# LargeDummyDevice register map
File version: 1.0
Registers are 32-bit, read-write, no defined reset value unless marked. A register's access mark holds for its fields unless they carry their own. Offsets are from the block's base; [hi:lo] are bit positions.

## PERIPHERAL_85
Base 0x40054000
0x04 REG_1 — Register 1
  [29:25] FIELD_4, [27:24] FIELD_2, [20:19] FIELD_1, [9:6] FIELD_3
0x08 REG_2 — Register 2
  [34:31] FIELD_4, [24:23] FIELD_1, [21] FIELD_7, [16:15] FIELD_2, [19:15] FIELD_5, [16:14] FIELD_3, [13:12] FIELD_6, [9] FIELD_8, [3:0] FIELD_9
0x0C REG_3 — Register 3
  [33:30] FIELD_4, [31:29] FIELD_8, [29:28] FIELD_1, [28:26] FIELD_13, [25] FIELD_7, [25:24] FIELD_6, [26:23] FIELD_17, [20:16] FIELD_2, [15] FIELD_14, [17:14] FIELD_11, [17:13] FIELD_10, [16:13] FIELD_12, [15:12] FIELD_16, [14:11] FIELD_3, [10] FIELD_15, [8:4] FIELD_9, [4:1] FIELD_5
0x10 REG_4 — Register 4
  [32:31] FIELD_18, [29] FIELD_20, [31:28] FIELD_13, [27] FIELD_2, [26:25] FIELD_12, [25:23] FIELD_19, [23:22] FIELD_16, [22:20] FIELD_15, [21:19] FIELD_11, [21:18] FIELD_4, [22:18] FIELD_14, [19:17] FIELD_6, [19:17] FIELD_8, [17:16] FIELD_10, [19:16] FIELD_17, [12:10] FIELD_7, [11:9] FIELD_5, [11:7] FIELD_9, [8:7] FIELD_21, [5:2] FIELD_3, [3:1] FIELD_1
0x14 REG_5 — Register 5
  [31] FIELD_16, [35:31] FIELD_24, [32:30] FIELD_7, [32:30] FIELD_8, [31:29] FIELD_21, [30:28] FIELD_17, [29:27] FIELD_12, [23:19] FIELD_3, [22:18] FIELD_13, [19:15] FIELD_2, [17:14] FIELD_18, [16:13] FIELD_9, [16:13] FIELD_23, [13:11] FIELD_19, [12:10] FIELD_15, [8:7] FIELD_14, [7:5] FIELD_5, [5] FIELD_10, [8:4] FIELD_4, [5:4] FIELD_6, [4:3] FIELD_1, [2] FIELD_11, [4:1] FIELD_20, [2:0] FIELD_22
0x18 REG_6 — Register 6
  [23:22] FIELD_3, [18:15] FIELD_1, [16:15] FIELD_2, [9:8] FIELD_4
0x1C REG_7 — Register 7
  [34:31] FIELD_7, [29:28] FIELD_4, [27:24] FIELD_2, [26:23] FIELD_1, [18:17] FIELD_3, [3:2] FIELD_5, [0] FIELD_6
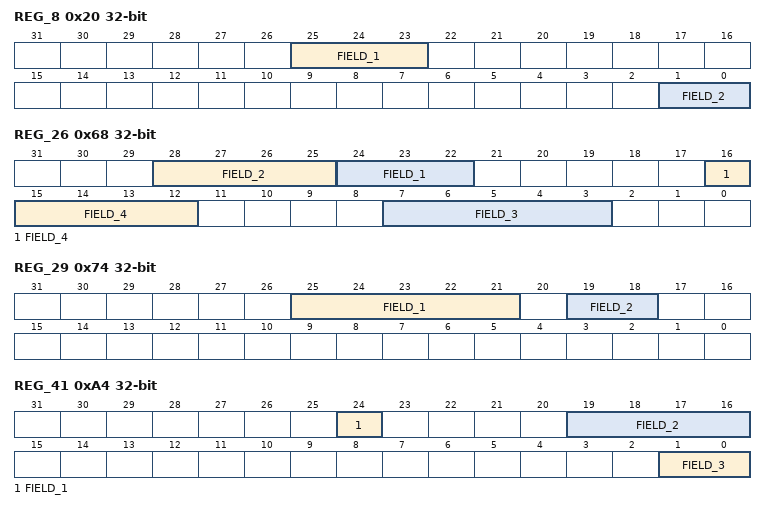
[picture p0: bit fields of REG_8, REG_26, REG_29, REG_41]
0x20 REG_8 — Register 8
  [25:23] FIELD_1, [1:0] FIELD_2
0x24 REG_9 — Register 9
  [18] FIELD_2, [10:8] FIELD_4, [9:7] FIELD_3, [7:4] FIELD_1
0x28 REG_10 — Register 10
  [28] FIELD_1, [32:28] FIELD_2, [16:14] FIELD_6, [8:4] FIELD_3, [0] FIELD_4, [2:0] FIELD_5
0x2C REG_11 — Register 11
  [33:31] FIELD_2, [33:31] FIELD_4, [32:31] FIELD_14, [26:23] FIELD_3, [23:20] FIELD_10, [23:19] FIELD_1, [19:15] FIELD_6, [18:14] FIELD_13, [13] FIELD_9, [13:12] FIELD_12, [10] FIELD_5, [7] FIELD_11, [7] FIELD_15, [6] FIELD_8, [6:4] FIELD_16, [3:0] FIELD_7
0x30 REG_12 — Register 12
  [33:30] FIELD_14, [32:29] FIELD_9, [26:25] FIELD_6, [26:22] FIELD_5, [18:16] FIELD_2, [18:16] FIELD_4, [16] FIELD_10, [19:15] FIELD_1, [15:13] FIELD_3, [15:13] FIELD_13, [12:8] FIELD_8, [9:7] FIELD_12, [5:4] FIELD_7, [4:2] FIELD_11
0x34 REG_13 — Register 13
  [31] FIELD_9, [31:28] FIELD_2, [30:28] FIELD_6, [27:23] FIELD_4, [24:22] FIELD_8, [14] FIELD_5, [15:13] FIELD_10, [10] FIELD_3, [11:9] FIELD_1, [8:5] FIELD_7
0x38 REG_14 — Register 14
  [32:31] FIELD_2, [30:28] FIELD_9, [31:28] FIELD_11, [28:24] FIELD_1, [27:23] FIELD_10, [23:22] FIELD_7, [15:14] FIELD_4, [13:11] FIELD_3, [8:7] FIELD_8, [6:4] FIELD_5, [7:4] FIELD_6, [6:4] FIELD_12, [5:2] FIELD_13, [6:2] FIELD_14
0x3C REG_15 — Register 15
  [33:30] FIELD_11, [33:29] FIELD_4, [30:29] FIELD_9, [28] FIELD_16, [31:27] FIELD_29, [26:24] FIELD_6, [24] FIELD_10, [28:24] FIELD_17, [26:22] FIELD_13, [22:19] FIELD_1, [20:19] FIELD_20, [22:18] FIELD_2, [21:17] FIELD_22, [20:17] FIELD_27, [18:15] FIELD_8, [15] FIELD_26, [14:13] FIELD_5, [14:12] FIELD_19, [13:12] FIELD_21, [11] FIELD_25, [14:10] FIELD_23, [12:8] FIELD_3, [8] FIELD_12, [8:5] FIELD_7, [5:4] FIELD_24, [5:3] FIELD_18, [4:3] FIELD_28, [5:2] FIELD_15, [4:1] FIELD_14
0x40 REG_16 — Register 16
  [33:29] FIELD_1, [33:29] FIELD_16, [31:28] FIELD_14, [29:27] FIELD_7, [25] FIELD_13, [25] FIELD_19, [23:22] FIELD_5, [21:19] FIELD_11, [15:14] FIELD_18, [14:13] FIELD_8, [17:13] FIELD_15, [12] FIELD_21, [11] FIELD_9, [9:7] FIELD_10, [11:7] FIELD_20, [8:6] FIELD_2, [8:4] FIELD_4, [4] FIELD_6, [6:3] FIELD_3, [5:3] FIELD_12, [7:3] FIELD_17
0x44 REG_17 — Register 17
  [28:27] FIELD_8, [26:25] FIELD_3, [23] FIELD_1, [16:15] FIELD_2, [18:14] FIELD_5, [11:10] FIELD_12, [9:7] FIELD_7, [4] FIELD_11, [2] FIELD_4, [6:2] FIELD_6, [2] FIELD_10, [1:0] FIELD_9
0x48 REG_18 — Register 18
  [31:29] FIELD_1, [9] FIELD_4, [4] FIELD_3, [4:2] FIELD_2
0x4C REG_19 — Register 19
  [34:31] FIELD_7, [34:30] FIELD_2, [31:28] FIELD_5, [27] FIELD_10, [27:26] FIELD_4, [26:25] FIELD_8, [28:25] FIELD_12, [27:23] FIELD_16, [27:23] FIELD_24, [23:21] FIELD_1, [23:21] FIELD_22, [20] FIELD_6, [20:18] FIELD_15, [20:17] FIELD_9, [17] FIELD_19, [17] FIELD_21, [15:14] FIELD_18, [16:14] FIELD_20, [14] FIELD_27, [14:13] FIELD_3, [13:11] FIELD_17, [11:9] FIELD_26, [8:7] FIELD_23, [8:5] FIELD_14, [2] FIELD_13, [2] FIELD_25, [3:1] FIELD_11
0x50 REG_20 — Register 20
  [21:19] FIELD_1
0x54 REG_21 — Register 21
  [30:29] FIELD_12, [33:29] FIELD_19, [28:27] FIELD_4, [29:26] FIELD_6, [25] FIELD_7, [24:23] FIELD_5, [25:23] FIELD_8, [22] FIELD_17, [23:21] FIELD_3, [22:18] FIELD_21, [18:17] FIELD_15, [19:17] FIELD_24, [16] FIELD_1, [17:15] FIELD_11, [16:15] FIELD_13, [16:14] FIELD_2, [14] FIELD_9, [16:12] FIELD_14, [12:10] FIELD_20, [13:10] FIELD_22, [10:7] FIELD_25, [7:6] FIELD_10, [6:5] FIELD_18, [3] FIELD_23, [2:1] FIELD_16
0x58 REG_22 — Register 22
  [35:31] FIELD_2, [31] FIELD_15, [30:27] FIELD_1, [27:26] FIELD_7, [27:24] FIELD_8, [24] FIELD_12, [17] FIELD_5, [16] FIELD_9, [17:15] FIELD_3, [11:9] FIELD_14, [10:6] FIELD_13, [7:5] FIELD_10, [6:4] FIELD_11, [3] FIELD_4, [1:0] FIELD_6
0x5C REG_23 — Register 23
  [31:30] FIELD_11, [33:30] FIELD_15, [29] FIELD_19, [29:27] FIELD_4, [29:27] FIELD_5, [28:27] FIELD_7, [31:27] FIELD_10, [31:27] FIELD_20, [26:25] FIELD_16, [29:25] FIELD_21, [28:24] FIELD_14, [23] FIELD_3, [26:23] FIELD_6, [21:19] FIELD_13, [17] FIELD_8, [17:15] FIELD_1, [18:15] FIELD_17, [11:8] FIELD_2, [8:5] FIELD_12, [4] FIELD_18, [3:0] FIELD_9
0x60 REG_24 — Register 24
  [35:31] FIELD_19, [33:29] FIELD_1, [29] FIELD_16, [30:27] FIELD_20, [27:24] FIELD_31, [25:22] FIELD_2, [23:22] FIELD_15, [21] FIELD_3, [22:21] FIELD_13, [19] FIELD_25, [22:18] FIELD_12, [22:18] FIELD_24, [20:17] FIELD_23, [18:17] FIELD_30, [16:15] FIELD_29, [18:14] FIELD_14, [15:12] FIELD_10, [13:12] FIELD_27, [12:10] FIELD_22, [13:9] FIELD_6, [7] FIELD_17, [7] FIELD_21, [9:6] FIELD_8, [7:5] FIELD_18, [4] FIELD_4, [4] FIELD_28, [5:3] FIELD_9, [6:2] FIELD_5, [4:0] FIELD_7, [1:0] FIELD_11, [3:0] FIELD_26
0x64 REG_25 — Register 25
  [26] FIELD_2, [18:15] FIELD_1, [16:12] FIELD_4, [11:7] FIELD_3
0x68 REG_26 — Register 26
  [28:25] FIELD_2, [24:22] FIELD_1, [16:12] FIELD_4, [7:3] FIELD_3
0x6C REG_27 — Register 27
  [35:31] FIELD_7, [30:29] FIELD_3, [28] FIELD_17, [28:26] FIELD_6, [28:26] FIELD_21, [25:24] FIELD_2, [26:22] FIELD_1, [20:19] FIELD_12, [22:18] FIELD_5, [21:18] FIELD_19, [20:16] FIELD_20, [14] FIELD_8, [13:11] FIELD_10, [11:9] FIELD_9, [11:8] FIELD_13, [10:8] FIELD_16, [11:7] FIELD_4, [3:2] FIELD_15, [5:2] FIELD_18, [4:1] FIELD_22, [3:0] FIELD_11, [1:0] FIELD_14
0x70 REG_28 — Register 28
  [31:27] FIELD_1, [28:24] FIELD_2, [26:24] FIELD_4, [15:14] FIELD_3, [14:13] FIELD_6, [14:10] FIELD_5
0x74 REG_29 — Register 29
  [25:21] FIELD_1, [19:18] FIELD_2
0x78 REG_30 — Register 30
  [35:31] FIELD_1, [32:31] FIELD_6, [31:30] FIELD_2, [34:30] FIELD_4, [34:30] FIELD_28, [31:29] FIELD_10, [32:28] FIELD_12, [31:28] FIELD_26, [30:26] FIELD_23, [25] FIELD_20, [22:19] FIELD_3, [20:18] FIELD_22, [17] FIELD_8, [16] FIELD_16, [16:15] FIELD_24, [15] FIELD_29, [19:15] FIELD_30, [13] FIELD_27, [14:12] FIELD_9, [16:12] FIELD_14, [15:12] FIELD_19, [11] FIELD_18, [13:9] FIELD_11, [8] FIELD_15, [11:8] FIELD_17, [10:6] FIELD_21, [7:5] FIELD_13, [5:4] FIELD_5, [7:4] FIELD_7, [5:2] FIELD_25, [4:0] FIELD_31
0x7C REG_31 — Register 31
  [33:31] FIELD_7, [32:29] FIELD_12, [30:28] FIELD_13, [31:27] FIELD_14, [25] FIELD_10, [28:24] FIELD_15, [24:23] FIELD_11, [25:21] FIELD_9, [13] FIELD_2, [17:13] FIELD_4, [12:11] FIELD_16, [14:10] FIELD_3, [9:8] FIELD_1, [9:5] FIELD_5, [6:5] FIELD_6, [3:2] FIELD_8
0x80 REG_32 — Register 32
  [32:29] FIELD_14, [29:28] FIELD_8, [31:27] FIELD_15, [28:27] FIELD_18, [27] FIELD_20, [18:17] FIELD_5, [17] FIELD_11, [20:17] FIELD_13, [20:17] FIELD_19, [14] FIELD_12, [14:13] FIELD_1, [13:11] FIELD_10, [14:10] FIELD_6, [10:7] FIELD_3, [4] FIELD_2, [7:3] FIELD_17, [5:1] FIELD_9, [4:0] FIELD_4, [2:0] FIELD_7, [2:0] FIELD_16
0x84 REG_33 — Register 33
  [32:28] FIELD_9, [28:27] FIELD_8, [30:26] FIELD_3, [28:26] FIELD_5, [23:22] FIELD_13, [22:21] FIELD_11, [13:9] FIELD_1, [10:7] FIELD_4, [6:3] FIELD_2, [5:2] FIELD_6, [3:0] FIELD_7, [4:0] FIELD_10, [3:0] FIELD_12
0x88 REG_34 — Register 34
  [26] FIELD_2, [19:17] FIELD_5, [12:11] FIELD_1, [3:2] FIELD_4, [3:0] FIELD_3
0x8C REG_35 — Register 35
  [31] FIELD_13, [31] FIELD_20, [33:30] FIELD_5, [29:28] FIELD_2, [31:27] FIELD_7, [31:27] FIELD_10, [28:27] FIELD_15, [24] FIELD_26, [26:23] FIELD_25, [24:22] FIELD_28, [20:18] FIELD_8, [18] FIELD_18, [18] FIELD_19, [21:18] FIELD_32, [20:17] FIELD_1, [16] FIELD_3, [15:14] FIELD_11, [18:14] FIELD_30, [13:12] FIELD_12, [12:11] FIELD_16, [8:6] FIELD_4, [6:4] FIELD_22, [4:3] FIELD_17, [3] FIELD_21, [7:3] FIELD_29, [3:2] FIELD_31, [1] FIELD_14, [4:0] FIELD_6, [0] FIELD_9, [2:0] FIELD_23, [4:0] FIELD_24, [4:0] FIELD_27
0x90 REG_36 — Register 36
  [31:28] FIELD_1, [28:27] FIELD_5, [26:25] FIELD_3, [21:18] FIELD_2, [16:14] FIELD_4
0x94 REG_37 — Register 37
  [31:30] FIELD_5, [32:30] FIELD_9, [31:30] FIELD_12, [30:28] FIELD_14, [24:20] FIELD_8, [23:20] FIELD_13, [18:15] FIELD_7, [16:13] FIELD_15, [16:12] FIELD_10, [13:12] FIELD_11, [16:12] FIELD_16, [15:11] FIELD_18, [14:10] FIELD_21, [13:9] FIELD_1, [9] FIELD_17, [11:7] FIELD_6, [10:7] FIELD_20, [5:4] FIELD_3, [7:3] FIELD_2, [3:2] FIELD_19, [4:1] FIELD_4
0x98 REG_38 — Register 38
  [33:31] FIELD_19, [33:31] FIELD_27, [30:29] FIELD_18, [30:27] FIELD_2, [28:24] FIELD_4, [24] FIELD_14, [26:23] FIELD_6, [27:23] FIELD_17, [25:23] FIELD_31, [21] FIELD_3, [21] FIELD_28, [20:19] FIELD_30, [20:18] FIELD_1, [19:18] FIELD_29, [19:17] FIELD_23, [18:15] FIELD_9, [16:15] FIELD_13, [15:14] FIELD_22, [17:13] FIELD_10, [16:13] FIELD_24, [16:13] FIELD_32, [13:11] FIELD_7, [13:10] FIELD_15, [9] FIELD_12, [10:8] FIELD_25, [6] FIELD_11, [9:6] FIELD_26, [8:4] FIELD_20, [4:3] FIELD_5, [6:3] FIELD_8, [3] FIELD_21, [3:1] FIELD_16
0x9C REG_39 — Register 39
  [32:31] FIELD_1, [29] FIELD_11, [29] FIELD_13, [29:25] FIELD_6, [24:23] FIELD_10, [16:14] FIELD_4, [17:14] FIELD_5, [16:12] FIELD_9, [8] FIELD_3, [11:7] FIELD_12, [9:5] FIELD_7, [4] FIELD_8, [7:3] FIELD_2, [4:3] FIELD_14, [2:0] FIELD_15
0xA0 REG_40 — Register 40
  [31:30] FIELD_1, [29] FIELD_10, [30:28] FIELD_14, [28] FIELD_15, [29:25] FIELD_11, [26:24] FIELD_24, [23:22] FIELD_16, [23:21] FIELD_9, [25:21] FIELD_23, [21:17] FIELD_28, [20:16] FIELD_13, [16:15] FIELD_27, [13] FIELD_6, [14:13] FIELD_12, [17:13] FIELD_30, [14:11] FIELD_4, [11] FIELD_7, [13:11] FIELD_22, [14:10] FIELD_21, [12:8] FIELD_18, [10:8] FIELD_20, [8] FIELD_25, [7] FIELD_17, [7] FIELD_29, [10:6] FIELD_5, [7:3] FIELD_26, [5:2] FIELD_8, [5:2] FIELD_19, [4:1] FIELD_2, [4:0] FIELD_3, [4:0] FIELD_31
0xA4 REG_41 — Register 41
  [24] FIELD_1, [19:16] FIELD_2, [1:0] FIELD_3
0xA8 REG_42 — Register 42
  [34:31] FIELD_20, [33:30] FIELD_9, [29] FIELD_3, [31:29] FIELD_14, [31:27] FIELD_6, [28:27] FIELD_17, [24] FIELD_1, [22] FIELD_12, [20:17] FIELD_4, [17:16] FIELD_10, [15:13] FIELD_7, [17:13] FIELD_13, [9] FIELD_16, [10:6] FIELD_15, [9:5] FIELD_11, [7:4] FIELD_19, [7:3] FIELD_8, [4:3] FIELD_18, [4:2] FIELD_2, [2:1] FIELD_5
0xAC REG_43 — Register 43
  [30:29] FIELD_22, [32:28] FIELD_12, [28] FIELD_16, [27] FIELD_8, [29:26] FIELD_20, [29:25] FIELD_13, [26:24] FIELD_21, [23] FIELD_2, [23] FIELD_3, [23:20] FIELD_14, [20] FIELD_19, [22:19] FIELD_5, [21:19] FIELD_9, [20:16] FIELD_4, [18:14] FIELD_18, [12:11] FIELD_11, [8] FIELD_10, [8:4] FIELD_15, [5:3] FIELD_1, [3:2] FIELD_7, [6:2] FIELD_17, [1:0] FIELD_6
0xB0 REG_44 — Register 44
  [29:25] FIELD_17, [26:23] FIELD_3, [21] FIELD_1, [21:19] FIELD_15, [19:18] FIELD_8, [22:18] FIELD_10, [18:17] FIELD_9, [18:17] FIELD_12, [16:15] FIELD_13, [17:13] FIELD_14, [12:11] FIELD_6, [9:7] FIELD_2, [8:7] FIELD_11, [8:5] FIELD_4, [6:5] FIELD_5, [5:2] FIELD_7, [4:0] FIELD_16
0xB4 REG_45 — Register 45
  [31] FIELD_5, [32:29] FIELD_22, [30:28] FIELD_13, [29:27] FIELD_2, [26:24] FIELD_6, [25:24] FIELD_11, [26:23] FIELD_7, [23:20] FIELD_10, [20:17] FIELD_12, [18:16] FIELD_8, [18:16] FIELD_18, [18:16] FIELD_20, [16:14] FIELD_14, [16:12] FIELD_15, [16:12] FIELD_16, [13:12] FIELD_21, [15:11] FIELD_9, [11:10] FIELD_3, [14:10] FIELD_19, [9:8] FIELD_23, [11:7] FIELD_4, [10:7] FIELD_17, [5:3] FIELD_1
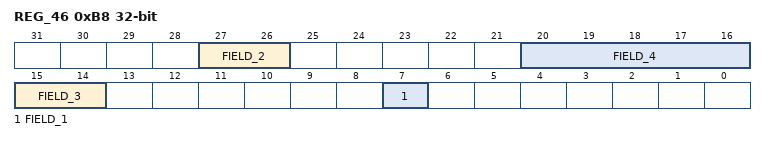
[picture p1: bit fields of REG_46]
0xB8 REG_46 — Register 46
  [27:26] FIELD_2, [20:16] FIELD_4, [15:14] FIELD_3, [7] FIELD_1
0xBC REG_47 — Register 47
  [33:31] FIELD_15, [31:30] FIELD_12, [28:26] FIELD_13, [26:25] FIELD_10, [25:21] FIELD_16, [19] FIELD_1, [21:19] FIELD_7, [21:19] FIELD_9, [21:18] FIELD_8, [17] FIELD_6, [12:10] FIELD_2, [10:9] FIELD_5, [7:3] FIELD_4, [2] FIELD_11, [4:0] FIELD_3, [3:0] FIELD_14
0xC0 REG_48 — Register 48
  [30] FIELD_1, [33:30] FIELD_6, [30:28] FIELD_17, [27] FIELD_3, [29:26] FIELD_8, [30:26] FIELD_10, [28:26] FIELD_18, [26:22] FIELD_16, [22:21] FIELD_7, [24:20] FIELD_19, [19:18] FIELD_2, [16] FIELD_4, [15:13] FIELD_12, [14:12] FIELD_14, [9] FIELD_20, [7:6] FIELD_5, [9:6] FIELD_11, [7:4] FIELD_21, [6:4] FIELD_22, [2:1] FIELD_9, [4:1] FIELD_13, [0] FIELD_15
0xC4 REG_49 — Register 49
  [31] FIELD_7, [31:29] FIELD_4, [29] FIELD_13, [30:29] FIELD_14, [31:29] FIELD_24, [32:28] FIELD_18, [29:27] FIELD_10, [29:26] FIELD_2, [28:26] FIELD_12, [27:24] FIELD_17, [24] FIELD_27, [24:20] FIELD_15, [18:17] FIELD_22, [18:14] FIELD_16, [13] FIELD_9, [12] FIELD_11, [14:10] FIELD_5, [10:8] FIELD_1, [11:8] FIELD_19, [12:8] FIELD_20, [10:7] FIELD_6, [7] FIELD_21, [6:5] FIELD_23, [9:5] FIELD_25, [8:4] FIELD_8, [5:2] FIELD_26, [5:1] FIELD_3
